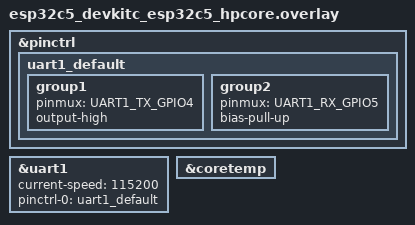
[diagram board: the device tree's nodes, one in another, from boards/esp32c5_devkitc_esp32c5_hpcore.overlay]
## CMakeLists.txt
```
# SPDX-License-Identifier: Apache-2.0

cmake_minimum_required(VERSION 3.20.0)
find_package(Zephyr REQUIRED HINTS $ENV{ZEPHYR_BASE})
project(app_more_services5)

zephyr_syscall_header(${CMAKE_CURRENT_SOURCE_DIR}/src/svc.h)

target_sources(app PRIVATE src/main.c src/svc.c)
```

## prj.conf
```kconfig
CONFIG_USERSPACE=y
CONFIG_APPLICATION_DEFINED_SYSCALL=y

CONFIG_SERIAL=y
CONFIG_UART_INTERRUPT_DRIVEN=n
CONFIG_SENSOR=y
CONFIG_WATCHDOG=y

CONFIG_LOG=y
CONFIG_LOG_MODE_MINIMAL=y
CONFIG_THREAD_NAME=y

CONFIG_MAIN_STACK_SIZE=4096
```

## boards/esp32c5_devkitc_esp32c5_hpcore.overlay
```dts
/*
 * Copyright (c) 2026 Espressif Systems (Shanghai) Co., Ltd.
 *
 * SPDX-License-Identifier: Apache-2.0
 */

#include <zephyr/dt-bindings/pinctrl/esp32c5-pinctrl.h>

/* Second UART: TX on GPIO4, RX on GPIO5 (free pins on the devkit). */
&pinctrl {
	uart1_default: uart1_default {
		group1 {
			pinmux = <UART1_TX_GPIO4>;
			output-high;
		};

		group2 {
			pinmux = <UART1_RX_GPIO5>;
			bias-pull-up;
		};
	};
};

&uart1 {
	status = "okay";
	current-speed = <115200>;
	pinctrl-0 = <&uart1_default>;
	pinctrl-names = "default";
};

/* Die-temperature sensor: enabled for the read-only service. */
&coretemp {
	status = "okay";
};
```

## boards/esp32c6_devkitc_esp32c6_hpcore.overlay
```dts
/*
 * Copyright (c) 2026 Espressif Systems (Shanghai) Co., Ltd.
 *
 * SPDX-License-Identifier: Apache-2.0
 */

#include <zephyr/dt-bindings/pinctrl/esp32c6-pinctrl.h>

/* Second UART: TX on GPIO4, RX on GPIO5 (free pins on the devkit). */
&pinctrl {
	uart1_default: uart1_default {
		group1 {
			pinmux = <UART1_TX_GPIO4>;
			output-high;
		};

		group2 {
			pinmux = <UART1_RX_GPIO5>;
			bias-pull-up;
		};
	};
};

&uart1 {
	status = "okay";
	current-speed = <115200>;
	pinctrl-0 = <&uart1_default>;
	pinctrl-names = "default";
};

/* Die-temperature sensor: enabled for the read-only service. */
&coretemp {
	status = "okay";
};
```

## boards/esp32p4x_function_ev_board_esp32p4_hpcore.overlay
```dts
/*
 * Copyright (c) 2026 Espressif Systems (Shanghai) Co., Ltd.
 *
 * SPDX-License-Identifier: Apache-2.0
 */

#include <zephyr/dt-bindings/pinctrl/esp32p4-pinctrl.h>

/* Second UART: TX on GPIO4, RX on GPIO5 (free pins on the devkit). */
&pinctrl {
	uart1_default: uart1_default {
		group1 {
			pinmux = <UART1_TX_GPIO4>;
			output-high;
		};

		group2 {
			pinmux = <UART1_RX_GPIO5>;
			bias-pull-up;
		};
	};
};

&uart1 {
	status = "okay";
	current-speed = <115200>;
	pinctrl-0 = <&uart1_default>;
	pinctrl-names = "default";
};

/* Die-temperature sensor: enabled for the read-only service. */
&coretemp {
	status = "okay";
};
```

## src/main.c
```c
/*
 * Copyright (c) 2026 Espressif Systems (Shanghai) Co., Ltd.
 *
 * SPDX-License-Identifier: Apache-2.0
 */

/*
 * An app using a scoped second UART, the die-temperature sensor, and a brokered
 * watchdog, all through service syscalls from user mode. The platform owns the
 * UART controller, the sensor, and the watchdog; the app only sends/receives
 * bytes, reads the temperature, and proves liveness by feeding its channel.
 */

#include "svc.h"

#include <zephyr/kernel.h>
#include <zephyr/sys/printk.h>
#include <errno.h>

#define STACK_SIZE 2048
#define APP_PRIO   5

K_THREAD_STACK_DEFINE(app_stack, STACK_SIZE);
static struct k_thread app_thread;

static void app_entry(void *p1, void *p2, void *p3)
{
	ARG_UNUSED(p1); ARG_UNUSED(p2); ARG_UNUSED(p3);

	for (int round = 0; round < 5; round++) {
		/* Watchdog: prove liveness this round. */
		int wd = svc_wdt_feed();

		/* Die temperature. */
		int32_t milli_c = 0;
		int rc = svc_die_temp(&milli_c);

		if (rc == 0) {
			printk("  [app] round %d: die temp = %d.%03d C, wdt=%d\n",
			       round, milli_c / 1000, milli_c % 1000, wd);
		} else {
			printk("  [app] round %d: die temp rc=%d, wdt=%d\n",
			       round, rc, wd);
		}

		/* Granted UART port 0: emit a line out the scoped port. */
		char line[40];
		int n = snprintk(line, sizeof(line), "temp=%d.%03dC\r\n",
				 milli_c / 1000, milli_c % 1000);
		svc_uart_write(0, (const uint8_t *)line, n);

		/* Poll the granted port for one input byte. */
		uint8_t in;

		if (svc_uart_read(0, &in) == 1) {
			printk("  [app] uart rx byte: 0x%02x\n", in);
		}

		k_msleep(500);
	}

	/* UART port 1 was NOT granted - the boundary rejects it. */
	uint8_t b = 'x';
	int rcu = svc_uart_write(1, &b, 1);

	printk("  [app] uart port 1 write -> rc=%d (expected -EPERM=%d, ungranted)\n",
	       rcu, -EPERM);

	printk("  [app] done - granted UART driven, ungranted denied\n");
}

int main(void)
{
	printk("\n*** more services 5: UART + die temp + watchdog (C6) ***\n");

	svc_wdt_install();

	/* Grant UART port 0 only; port 1 stays denied. */
	svc_uart_grant(BIT(0));

	k_tid_t t = k_thread_create(&app_thread, app_stack, STACK_SIZE, app_entry,
				    NULL, NULL, NULL, APP_PRIO, K_USER, K_FOREVER);

	k_thread_start(t);
	k_thread_join(t, K_FOREVER);

	printk("\n*** done ***\n");
	return 0;
}
```

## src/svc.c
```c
/*
 * Copyright (c) 2026 Espressif Systems (Shanghai) Co., Ltd.
 *
 * SPDX-License-Identifier: Apache-2.0
 */

#include "svc.h"

#include <zephyr/kernel.h>
#include <zephyr/device.h>
#include <zephyr/drivers/uart.h>
#include <zephyr/drivers/sensor.h>
#include <zephyr/drivers/watchdog.h>
#include <zephyr/internal/syscall_handler.h>
#include <errno.h>

#define UART_MAX 64

/*
 * The platform owns the UART ports and grants the app a subset. Port 0 is the
 * usable second UART (uart1); port 1 is a second managed port left ungranted to
 * show the boundary. The app reaches a granted port only as a byte channel.
 */
static const struct device *const uart_port[] = {
	DEVICE_DT_GET(DT_NODELABEL(uart1)),
	DEVICE_DT_GET(DT_NODELABEL(uart0)),
};
#define UART_COUNT ARRAY_SIZE(uart_port)

/* Per-port grant: bit N set means the app may use UART port N. */
static uint32_t uart_grant;

void svc_uart_grant(uint32_t port_mask)
{
	uart_grant = port_mask;
}

/* The platform owns the die-temp sensor (open, read-only to apps). */
static const struct device *const temp_dev = DEVICE_DT_GET(DT_ALIAS(die_temp0));

/* The platform installs and owns the watchdog; the app feeds its channel. */
static const struct device *const wdt_dev = DEVICE_DT_GET(DT_NODELABEL(wdt0));
static int app_wdt_chan = -1;

void svc_wdt_install(void)
{
	if (!device_is_ready(wdt_dev)) {
		return;
	}

	struct wdt_timeout_cfg cfg = {
		.window.min = 0U,
		.window.max = 8000U,
		.callback = NULL,
		.flags = WDT_FLAG_RESET_SOC,
	};

	app_wdt_chan = wdt_install_timeout(wdt_dev, &cfg);
	if (app_wdt_chan >= 0) {
		wdt_setup(wdt_dev, WDT_OPT_PAUSE_HALTED_BY_DBG);
	}
}

int z_impl_svc_uart_write(int port, const uint8_t *buf, size_t len)
{
	if (port < 0 || port >= (int)UART_COUNT ||
	    !device_is_ready(uart_port[port]) || len > UART_MAX) {
		return -ENODEV;
	}
	for (size_t i = 0; i < len; i++) {
		uart_poll_out(uart_port[port], buf[i]);
	}
	return (int)len;
}

int z_impl_svc_uart_read(int port, uint8_t *out)
{
	if (port < 0 || port >= (int)UART_COUNT ||
	    !device_is_ready(uart_port[port])) {
		return -ENODEV;
	}
	int rc = uart_poll_in(uart_port[port], out);

	return (rc == 0) ? 1 : -EAGAIN;
}

int z_impl_svc_die_temp(int32_t *milli_c)
{
	if (!device_is_ready(temp_dev)) {
		return -ENODEV;
	}
	int rc = sensor_sample_fetch(temp_dev);

	if (rc != 0) {
		return rc;
	}

	struct sensor_value v;

	rc = sensor_channel_get(temp_dev, SENSOR_CHAN_DIE_TEMP, &v);
	if (rc != 0) {
		return rc;
	}

	*milli_c = v.val1 * 1000 + v.val2 / 1000;
	return 0;
}

int z_impl_svc_wdt_feed(void)
{
	if (app_wdt_chan < 0) {
		return -ENODEV;
	}
	return wdt_feed(wdt_dev, app_wdt_chan);
}

#ifdef CONFIG_USERSPACE
static inline int z_vrfy_svc_uart_write(int port, const uint8_t *buf, size_t len)
{
	if (port < 0 || port >= (int)UART_COUNT || (uart_grant & BIT(port)) == 0U) {
		return -EPERM;
	}
	if (len > UART_MAX) {
		return -EINVAL;
	}
	K_OOPS(K_SYSCALL_MEMORY_READ(buf, len));
	return z_impl_svc_uart_write(port, buf, len);
}
#include <zephyr/syscalls/svc_uart_write_mrsh.c>

static inline int z_vrfy_svc_uart_read(int port, uint8_t *out)
{
	if (port < 0 || port >= (int)UART_COUNT || (uart_grant & BIT(port)) == 0U) {
		return -EPERM;
	}
	K_OOPS(K_SYSCALL_MEMORY_WRITE(out, sizeof(*out)));
	return z_impl_svc_uart_read(port, out);
}
#include <zephyr/syscalls/svc_uart_read_mrsh.c>

static inline int z_vrfy_svc_die_temp(int32_t *milli_c)
{
	K_OOPS(K_SYSCALL_MEMORY_WRITE(milli_c, sizeof(*milli_c)));
	return z_impl_svc_die_temp(milli_c);
}
#include <zephyr/syscalls/svc_die_temp_mrsh.c>

static inline int z_vrfy_svc_wdt_feed(void)
{
	return z_impl_svc_wdt_feed();
}
#include <zephyr/syscalls/svc_wdt_feed_mrsh.c>
#endif
```

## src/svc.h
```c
/*
 * Copyright (c) 2026 Espressif Systems (Shanghai) Co., Ltd.
 *
 * SPDX-License-Identifier: Apache-2.0
 */

#ifndef APP_MORE_SERVICES5_SVC_H_
#define APP_MORE_SERVICES5_SVC_H_

#include <zephyr/kernel.h>

/*
 * A fifth batch: a scoped second serial port, the chip die-temperature sensor,
 * and a brokered watchdog feed.
 *
 *   svc_uart_write - send bytes on the platform-owned second UART (scoped, like
 *                    SPI/I2C: the platform owns the controller, the app sends
 *                    bytes).
 *   svc_uart_read  - poll a byte from the second UART; -EAGAIN if none waiting.
 *   svc_die_temp   - the chip core temperature in milli-degrees Celsius (open,
 *                    read-only).
 *   svc_wdt_feed   - feed the app's watchdog channel; the platform installs and
 *                    owns the watchdog, the app proves liveness through this.
 */

/* Scoped: write @len bytes out granted UART @port. Returns count sent. */
__syscall int svc_uart_write(int port, const uint8_t *buf, size_t len);

/* Scoped: poll one byte from granted UART @port; 1 on a byte, -EAGAIN if none. */
__syscall int svc_uart_read(int port, uint8_t *out);

/* Supervisor-only: grant the app a set of UART ports (bit N = port N). */
void svc_uart_grant(uint32_t port_mask);

/* Open: core die temperature in milli-degrees C. */
__syscall int svc_die_temp(int32_t *milli_c);

/* Brokered: prove liveness on the app's watchdog channel. */
__syscall int svc_wdt_feed(void);

/* Supervisor-only: install and start the watchdog before launching the app. */
void svc_wdt_install(void);

#include <zephyr/syscalls/svc.h>

#endif /* APP_MORE_SERVICES5_SVC_H_ */
```
